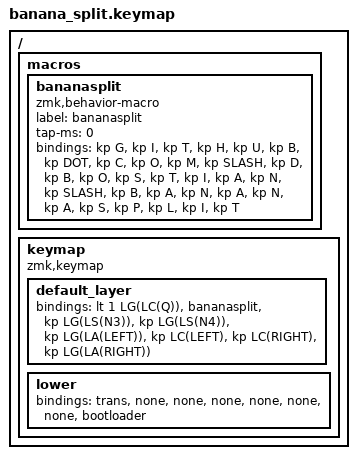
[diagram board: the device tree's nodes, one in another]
/*
 * Copyright (c) 2022 Dan Bostian
 * SPDX-License-Identifier: MIT
 */

#include <behaviors.dtsi>
#include <dt-bindings/zmk/keys.h>
#include <dt-bindings/zmk/bt.h>
#include <dt-bindings/zmk/ext_power.h>
#include <dt-bindings/zmk/outputs.h>

/ {
    // https://github.com/dbostian/bananasplit
    macros {
        bananasplit: bananasplit {
            label = "bananasplit";
            compatible = "zmk,behavior-macro";
            #binding-cells = <0>;
            tap-ms = <0>;
            bindings
                = <&kp G &kp I &kp T &kp H &kp U &kp B &kp DOT &kp C &kp O &kp M &kp SLASH>
                , <&kp D &kp B &kp O &kp S &kp T &kp I &kp A &kp N &kp SLASH>
                , <&kp B &kp A &kp N &kp A &kp N &kp A &kp S &kp P &kp L &kp I &kp T>
                ;
        };
    };

    keymap {
        compatible =  "zmk,keymap" ;

        default_layer {
            bindings = <
                &lt 1 LG(LC(Q)) &bananasplit &kp LG(LS(N3)) &kp LG(LS(N4))           &kp LG(LA(LEFT)) &kp LC(LEFT) &kp LC(RIGHT) &kp LG(LA(RIGHT))
            >; 
        };

        lower {
            bindings = <
                &trans &none &none &none                                       &none &none &none &bootloader
            >; 
        };

    };
};
